# PY32F031xx register map
Vendor: Puya; Series: PY32F0; File version: 1.0.0
CPU: CM0+ r0p1, little endian, no MPU, no FPU, 4 interrupt priority bits
Registers are 32-bit, read-write, reset 0x0 unless marked. A register's access mark holds for its fields unless they carry their own. Offsets are from the block's base; [hi:lo] are bit positions; {n}, {i} and the like mark numbered series.

## IWDG — Independent watchdog
Base 0x40003000
0x00 KR wo — Key register (IWDG_KR)
  [15:0] KEY — Key value
0x04 PR — Prescaler register (IWDG_PR)
  [2:0] PR — Prescaler divider
0x08 RLR reset 0xFFF — Reload register (IWDG_RLR)
  [11:0] RL — Watchdog counter reload value
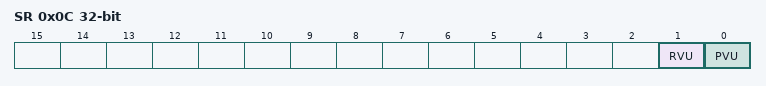
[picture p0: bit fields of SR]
0x0C SR ro — Status register (IWDG_SR)
  [1] RVU — Watchdog counter reload value update
  [0] PVU — Watchdog prescaler value update

## WWDG — Window watchdog
Base 0x40002C00
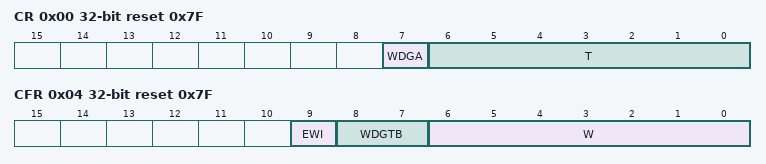
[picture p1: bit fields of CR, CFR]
0x00 CR reset 0x7F — Control register (WWDG_CR)
  [7] WDGA — Activation bit
  [6:0] T — 7-bit counter (MSB to LSB)
0x04 CFR reset 0x7F — Configuration register (WWDG_CFR)
  [9] EWI — Early Wakeup Interrupt
  [8:7] WDGTB — Timer Base
  [6:0] W — 7-bit window value
0x08 SR — Status register (WWDG_SR)
  [0] EWIF — Early Wakeup Interrupt flag

## LCD — LCD CONTROLLER
Base 0x40002400
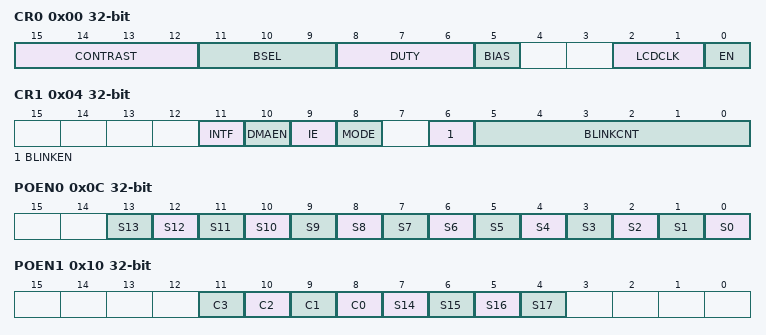
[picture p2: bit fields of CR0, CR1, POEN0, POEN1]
0x00 CR0 — Control register
  [15:12] CONTRAST, [11:9] BSEL, [8:6] DUTY, [5] BIAS, [2:1] LCDCLK, [0] EN
0x04 CR1
  [11] INTF, [10] DMAEN, [9] IE, [8] MODE, [6] BLINKEN, [5:0] BLINKCNT
0x08 INTCLR
  [10] INTF_CLR
0x0C POEN0
  [n] S{n} (n=0..13)
0x10 POEN1
  [n+8] C{n} (n=0..3), [21-n] S{n} (n=14..17)
{0x14+4i} RAM{i} (i=0..3) — des RAM{i}
  [31:0] D — des D
0x24 RAM4 — des RAM4
  [15:0] D — des D

## TIM14 — General purpose timer
Base 0x40002000
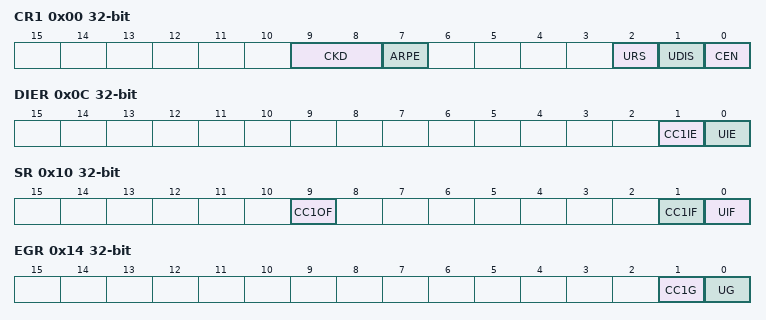
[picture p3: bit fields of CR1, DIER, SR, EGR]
0x00 CR1 — TIM14 control register1
  [9:8] CKD — Prescaler factor
  [7] ARPE — Auto-reload preload enable
  [2] URS — Update request source
  [1] UDIS — Update disable
  [0] CEN — Counter enable
0x0C DIER — DMA/Interrupt enable register
  [1] CC1IE — Compare/
  [0] UIE — Update interrupt enable
0x10 SR — status register
  [9] CC1OF — Compare/capture 1 flag
  [1] CC1IF — Compare/capture 1 interrupt flag
  [0] UIF — Update interrupt flag
0x14 EGR wo — event generation register
  [1] CC1G — Compare/capture1 event
  [0] UG — Update generation
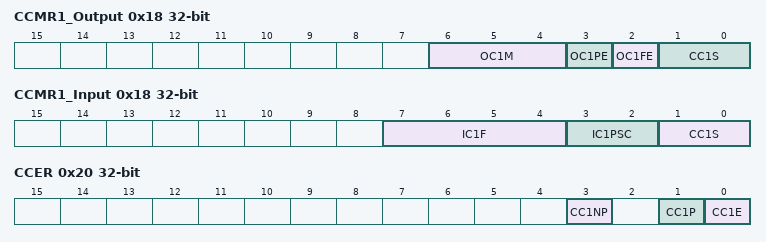
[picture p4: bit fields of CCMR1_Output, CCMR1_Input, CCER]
0x18 CCMR1_Output — capture/compare mode register (output mode)
  [6:4] OC1M — Output Compare 1 mode
  [3] OC1PE — Output Compare 1 preload enable
  [2] OC1FE — Output Compare 1 fast enable
  [1:0] CC1S — Capture/Compare 1 selection
0x18 CCMR1_Input (alternate view of CCMR1_Output) — capture/compare mode register 1 (input mode)
  [7:4] IC1F — Input capture 1 filter
  [3:2] IC1PSC — Input capture 1 prescaler
  [1:0] CC1S — Capture/Compare 1 selection
0x20 CCER — capture/compare enable register
  [3] CC1NP — Capture/Compare 1 output Polarity
  [1] CC1P — Capture/Compare 1 output Polarity
  [0] CC1E — Capture/Compare 1 output enable
0x24 CNT — counter
  [15:0] CNT — counter value
0x28 PSC — prescaler
  [15:0] PSC — Prescaler value
0x2C ARR — auto-reload register
  [15:0] ARR — Auto-reload value
0x34 CCR1 — capture/compare register 1
  [15:0] CCR1 — Capture/Compare 1 value
0x50 OR — Option register
  [1:0] TI1_RMP — TIM14 channel1 input remap

## TIM16 — General purpose timer
Base 0x40014400
Same registers: TIM17 0x40014800
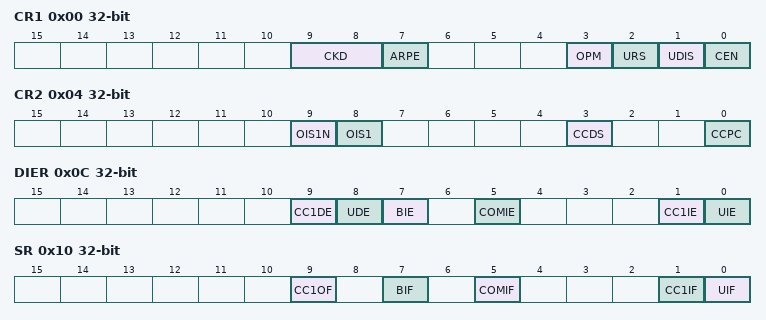
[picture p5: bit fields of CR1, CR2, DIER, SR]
0x00 CR1 — TIM16 control register1
  [9:8] CKD — Prescaler factor
  [7] ARPE — Auto-reload preload enable
  [3] OPM — One pulse mode
  [2] URS — Update request source
  [1] UDIS — Update disable
  [0] CEN — Counter enable
0x04 CR2 — control register 2
  [9] OIS1N — Output Idle state 1
  [8] OIS1 — Output Idle state 1
  [3] CCDS — Capture/compare DMA selection
  [0] CCPC — Capture/compare preloaded control
0x0C DIER — DMA/Interrupt enable register
  [9] CC1DE — Compare/capture DMA requeset enable
  [8] UDE — Update DMA request enable
  [7] BIE — Break interrupt enable
  [5] COMIE — Com interrupt enable
  [1] CC1IE — Capture/Compare 1 interrupt enable
  [0] UIE — Update interrupt enable
0x10 SR — status register
  [9] CC1OF — Update interrupt flag
  [7] BIF — Break interrupt flag
  [5] COMIF — Com interrupt flag
  [1] CC1IF — Capture/Compare 1 interrupt flag
  [0] UIF — Update interrupt flag
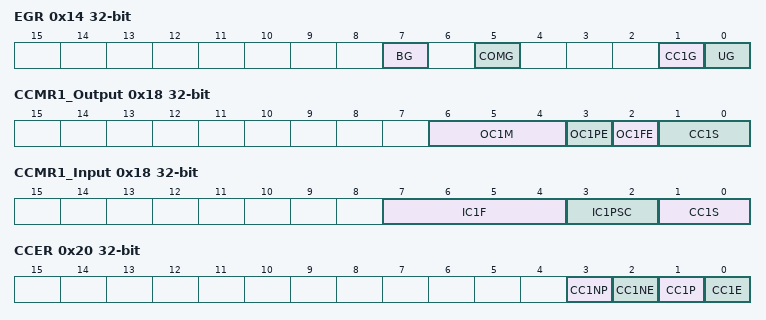
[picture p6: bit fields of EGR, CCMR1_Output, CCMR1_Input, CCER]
0x14 EGR wo — event generation register
  [7] BG — Break event generation
  [5] COMG — COM evnet generation
  [1] CC1G — Capture/Compare 1 generation
  [0] UG — Update generation
0x18 CCMR1_Output — capture/compare mode register (output mode)
  [6:4] OC1M — Output Compare 1 mode
  [3] OC1PE — Output Compare 1 preload enable
  [2] OC1FE — Output Compare 1 fast enable
  [1:0] CC1S — Capture/Compare 1 selection
0x18 CCMR1_Input (alternate view of CCMR1_Output) — capture/compare mode register 1 (input mode)
  [7:4] IC1F — Input capture 1 filter
  [3:2] IC1PSC — Input capture 1 prescaler
  [1:0] CC1S — Capture/Compare 1 selection
0x20 CCER — capture/compare enable register
  [3] CC1NP — Capture/Compare 1 output Polarity
  [2] CC1NE — Capture/Compare 1 complementary output enable
  [1] CC1P — Capture/Compare 1 output Polarity
  [0] CC1E — Capture/Compare 1 output enable
0x24 CNT — counter
  [15:0] CNT — counter value
0x28 PSC — prescaler
  [15:0] PSC — Prescaler value
0x2C ARR — auto-reload register
  [15:0] ARR — Auto-reload value
0x30 RCR — repetition counter register
  [7:0] REP — Repetition counter value
0x34 CCR1 — capture/compare register 1
  [15:0] CCR1 — Capture/Compare 1 value
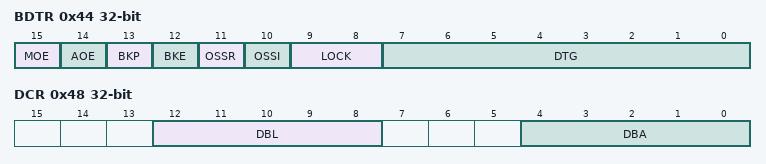
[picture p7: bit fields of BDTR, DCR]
0x44 BDTR — break and dead-time register
  [15] MOE — Main output enable
  [14] AOE — Automatic output enable
  [13] BKP — Break polarity
  [12] BKE — Break enable
  [11] OSSR — Off-state selection for Run mode
  [10] OSSI — Off-state selection for Idle mode
  [9:8] LOCK — Lock configuration
  [7:0] DTG — Dead-time generator setup
0x48 DCR — DMA control register
  [12:8] DBL — DMA burst length
  [4:0] DBA — DMA base address
0x4C DMAR — DMA address for full transfer
  [31:0] DMAB — DMA register for burst accesses
